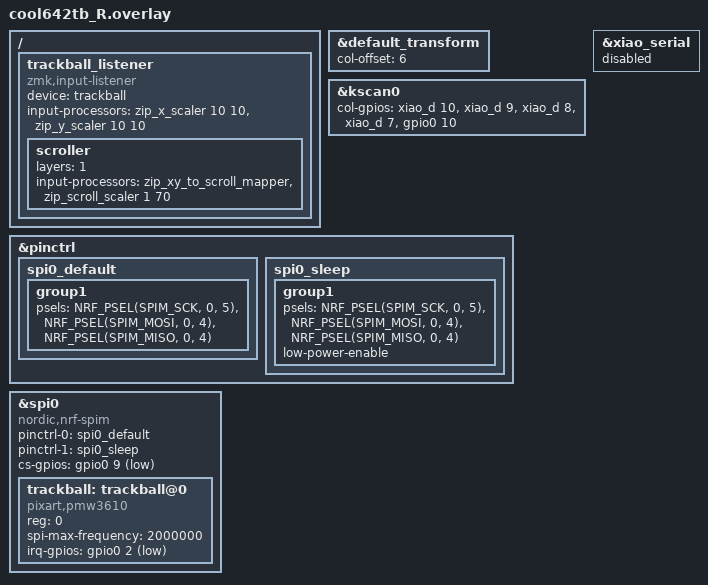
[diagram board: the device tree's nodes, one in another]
#include "cool642tb.dtsi"

/* Input Processor を使う */
#include <input/processors.dtsi>
#include <dt-bindings/zmk/input_transform.h>

&default_transform {
    col-offset = <6>;
};

&kscan0 {
    col-gpios
        = <&xiao_d 10 GPIO_ACTIVE_HIGH>
        , <&xiao_d 9 GPIO_ACTIVE_HIGH>
        , <&xiao_d 8 GPIO_ACTIVE_HIGH>
        , <&xiao_d 7 GPIO_ACTIVE_HIGH>
        , <&gpio0 10 GPIO_ACTIVE_HIGH>
        ;
};

/ {
    trackball_listener: trackball_listener {
        compatible = "zmk,input-listener";
        device = <&trackball>;

        /*
         * 1) 追従改善のため「増幅」をやめる（まずは等倍）
         *   - 速い動きで頭打ち/飽和っぽくなるのを避ける狙い
         *   - 感度が足りない場合は、まずCPI側を上げるか、
         *     ここを 9/10, 8/10… のように「減衰方向」で調整推奨
         */
        input-processors =
            <&zip_x_scaler 10 10>,
            <&zip_y_scaler 10 10>;

        /*
         * スクロール（レイヤ1のときだけ）
         *  - 追従の切り分けを最優先なら、ここも一旦コメントアウト推奨
         */
        scroller {
            layers = <1>;
            input-processors =
                <&zip_xy_to_scroll_mapper>,
                <&zip_scroll_scaler 1 70>;
        };
    };
};

&pinctrl {
    spi0_default: spi0_default {
        group1 {
            psels = <NRF_PSEL(SPIM_SCK, 0, 5)>,
                <NRF_PSEL(SPIM_MOSI, 0, 4)>,
                <NRF_PSEL(SPIM_MISO, 0, 4)>;
        };
    };

    spi0_sleep: spi0_sleep {
        group1 {
            psels = <NRF_PSEL(SPIM_SCK, 0, 5)>,
                <NRF_PSEL(SPIM_MOSI, 0, 4)>,
                <NRF_PSEL(SPIM_MISO, 0, 4)>;
            low-power-enable;
        };
    };
};

&xiao_serial { status = "disabled"; };

&spi0 {
    status = "okay";
    compatible = "nordic,nrf-spim";
    pinctrl-0 = <&spi0_default>;
    pinctrl-1 = <&spi0_sleep>;
    pinctrl-names = "default", "sleep";
    cs-gpios = <&gpio0 9 GPIO_ACTIVE_LOW>;

    trackball: trackball@0 {
        status = "okay";
        compatible = "pixart,pmw3610";
        reg = <0>;
        spi-max-frequency = <2000000>;
        irq-gpios = <&gpio0 2 (GPIO_ACTIVE_LOW | GPIO_PULL_UP)>;

        /*
         * 2) automouse-layer を無効化
         *    - レイヤーが勝手に揺れて追従/体感を崩すのを避ける
         */
        // automouse-layer = <4>;

        /*
         * Input Processor でスクロール化するので、ドライバ側の scroll-layers は使わない
         * 二重に効くのを避けるためオフ
         */
        // scroll-layers = <1>;
    };
};
